# FM33L0XXD register map
File version: 1.0
CPU: SC000 r1p0, little endian, no MPU, FPU, 8 interrupt priority bits
Registers are 32-bit, read-write, reset 0x0 unless marked. A register's access mark holds for its fields unless they carry their own. Offsets are from the block's base; [hi:lo] are bit positions; {n}, {i} and the like mark numbered series.

## RCC — RCC module information
Base 0x4000020C
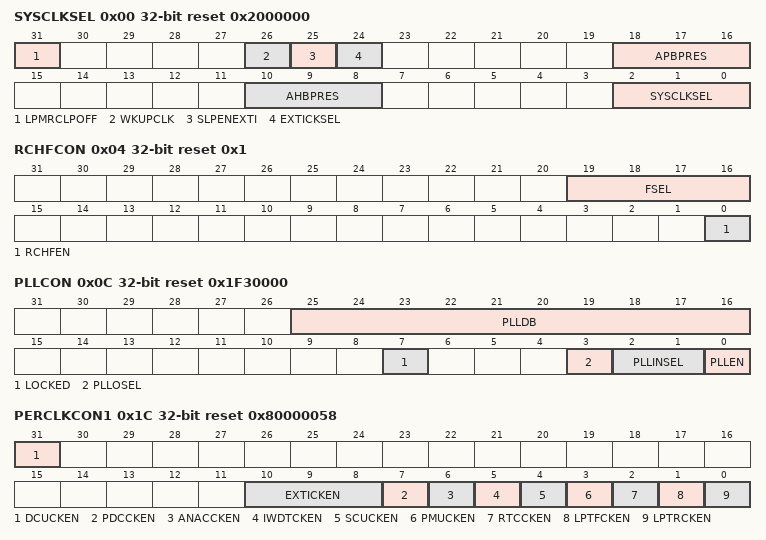
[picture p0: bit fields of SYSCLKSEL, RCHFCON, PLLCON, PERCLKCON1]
0x00 SYSCLKSEL reset 0x2000000
  [31] LPMRCLPOFF — LPM_RCLP_OFF field description
  [26] WKUPCLK — WKUPCLK field description
  [25] SLPENEXTI — SLP_ENEXTI field description
  [24] EXTICKSEL — EXTICKSEL field description
  [18:16] APBPRES — APBPRES field description
  [10:8] AHBPRES — AHBPRES field description
  [2:0] SYSCLKSEL — SYSCLKSEL field description
0x04 RCHFCON reset 0x1
  [19:16] FSEL — FSEL field description
  [0] RCHFEN — RCHFEN field description
0x08 RCHFTRIM reset 0x400
  [6:0] RCHFTRIM — RCHFTRIM field description
0x0C PLLCON reset 0x1F30000
  [25:16] PLLDB — PLLDB field description
  [7] LOCKED ro — LOCKED field description
  [3] PLLOSEL — PLLOSEL field description
  [2:1] PLLINSEL — PLLINSEL field description
  [0] PLLEN — PLLEN field description
0x10 RCLPCON
  [0] RCLPENB ro — RCLP_ENB field description
0x14 RCLPTRIM reset 0x8
  [3:0] RCLPTRIM — RCLP_TRIM field description
0x18 XTLFIPW
  [2:0] XTLFIPW — XTLFIPW field description
0x1C PERCLKCON1 reset 0x80000058
  [31] DCUCKEN — DCUCKEN field description
  [10:8] EXTICKEN — EXTICKEN field description
  [7] PDCCKEN — PDCCKEN field description
  [6] ANACCKEN — ANACCKEN field description
  [5] IWDTCKEN — IWDTCKEN field description
  [4] SCUCKEN — SCUCKEN field description
  [3] PMUCKEN — PMUCKEN field description
  [2] RTCCKEN — RTCCKEN field description
  [1] LPTFCKEN — LPTFCKEN field description
  [0] LPTRCKEN — LPTRCKEN field description
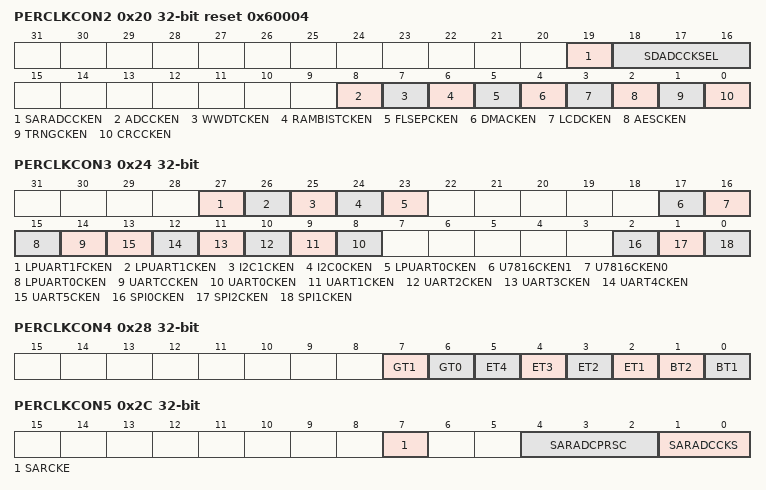
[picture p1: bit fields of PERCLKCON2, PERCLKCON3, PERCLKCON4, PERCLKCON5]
0x20 PERCLKCON2 reset 0x60004
  [19] SARADCCKEN — SARADCCKEN field description
  [18:16] SDADCCKSEL — SDADCCKSEL field description
  [8] ADCCKEN — ADCCKEN field description
  [7] WWDTCKEN — WWDTCKEN field description
  [6] RAMBISTCKEN — RAMBISTCKEN field description
  [5] FLSEPCKEN — FLSEPCKEN field description
  [4] DMACKEN — DMACKEN field description
  [3] LCDCKEN — LCDCKEN field description
  [2] AESCKEN — AESCKEN field description
  [1] TRNGCKEN — TRNGCKEN field description
  [0] CRCCKEN — CRCCKEN field description
0x24 PERCLKCON3
  [27] LPUART1FCKEN — LPUART1FCKEN field description
  [26] LPUART1CKEN — LPUART1CKEN field description
  [25] I2C1CKEN — I2C1CKEN field description
  [24] I2C0CKEN — I2C0CKEN field description
  [23] LPUART0CKEN — LPUART0CKEN field description
  [17] U7816CKEN1 — U7816CKEN1 field description
  [16] U7816CKEN0 — U7816CKEN0 field description
  [15] LPUART0CKEN — LPUART0CKEN field description
  [14] UARTCCKEN — UARTCCKEN field description
  [n+8] UART{n}CKEN (n=0..5) — UART{n}CKEN field description
  [2] SPI0CKEN — SPI0CKEN field description
  [1] SPI2CKEN — SPI2CKEN field description
  [0] SPI1CKEN — SPI1CKEN field description
0x28 PERCLKCON4
  [7] GT1 CKE — GT1 CKE field description
  [6] GT0 CKE — GT0 CKE field description
  [n+1] ET{n} CKE (n=1..4) — ET{n} CKE field description
  [1] BT2 CKE — BT2 CKE field description
  [0] BT1 CKE — BT1 CKE field description
0x2C PERCLKCON5
  [7] SARCKE — SARCKE field description
  [4:2] SARADCPRSC — SARADCPRSC field description
  [1:0] SARADCCKS — SARADCCKS field description
0x38 MPRIL
  [0] MPRIL — MPRIL field description
0x3C RCLFCON
  [0] RCLFENB ro — RCLF_ENB field description
0x40 RCLFTRIM reset 0x20
  [5:0] RCLFTRIM — RCLF_TRIM field description
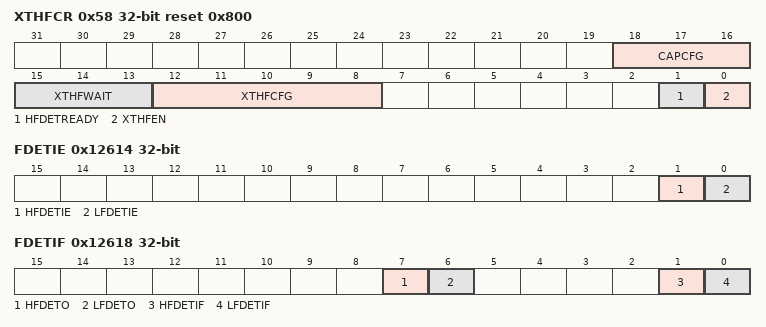
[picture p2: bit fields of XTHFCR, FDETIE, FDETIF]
0x58 XTHFCR reset 0x800
  [18:16] CAPCFG — CAP_CFG field description
  [15:13] XTHFWAIT — XTHF_WAIT field description
  [12:8] XTHFCFG — XTHF_CFG field description
  [1] HFDETREADY ro — HFDET_READY field description
  [0] XTHFEN — XTHFEN field description
0x12614 FDETIE — FDETIF Register
  [1] HFDETIE — HFDET_IE field description
  [0] LFDETIE — LFDET_IE field description
0x12618 FDETIF
  [7] HFDETO ro — HFDETO field description
  [6] LFDETO ro — LFDETO field description
  [1] HFDETIF — HFDET_IF field description
  [0] LFDETIF — LFDET_IF field description
